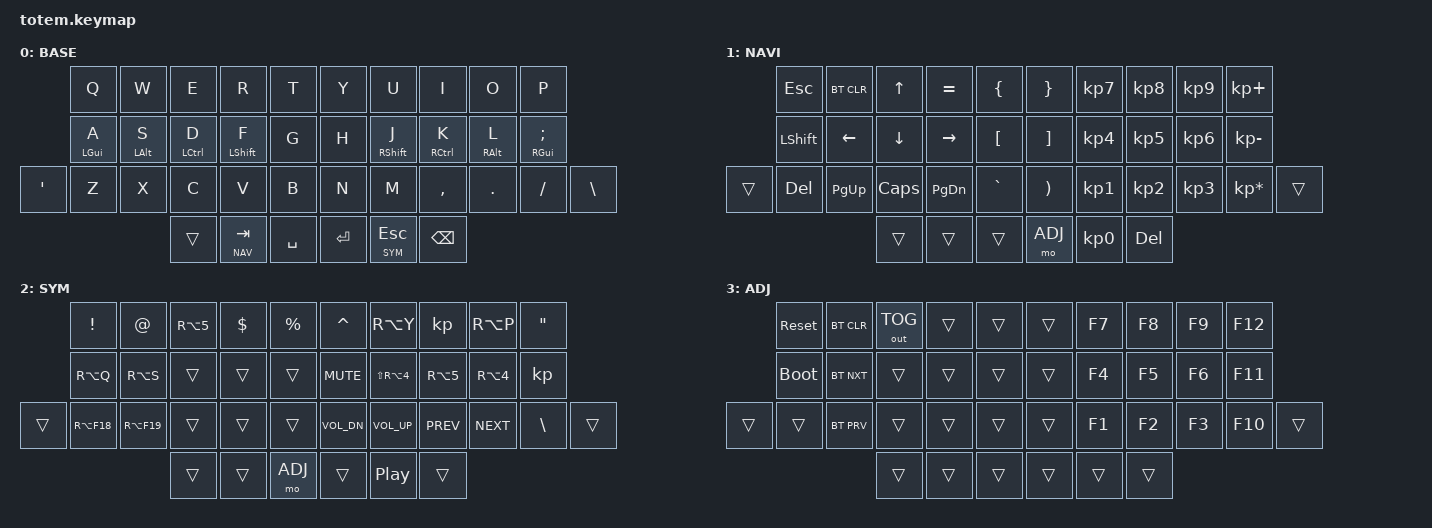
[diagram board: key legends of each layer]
//
//                                                        ▀▀▀▀▀     ▀▀▀▀▀          ▀▀█▀▀
//                                                        ▄▀▀▀▄  ▄  ▄▀▀▀▄  ▄  ▄▀▀▀▄  █  ▄▀▀▀▄
//                                                        █   █  █  █   █  █  █   █  █  █   █
//                                                         ▀▀▀   █   ▀▀▀   █   ▀▀▀   ▀   ▀▀▀
//                                                               █      ▄▄▄█▄▄▄    █   █  
//                                                               ▀      █  █  █     █▄█
//                                                             ▀▀▀▀▀    █  █  █      ▀
//                                                                      ▀  ▀  ▀
//
// ▄▄▄▄▄▄▄▄▄▄▄▄▄▄▄▄▄▄▄▄▄▄▄▄▄▄▄▄▄▄▄▄▄▄▄▄▄▄▄▄▄▄▄▄▄▄▄▄▄▄▄▄▄▄▄▄▄▄▄▄▄▄▄▄▄▄▄▄▄▄▄▄▄▄▄▄▄▄▄▄▄▄▄▄▄▄▄▄▄▄▄▄▄▄▄▄▄▄▄▄▄▄▄▄▄▄▄▄▄▄▄▄▄▄▄▄▄▄▄▄▄▄▄▄▄▄▄▄▄▄▄▄▄▄▄▄▄▄▄▄▄▄▄▄▄▄▄▄▄

#include <behaviors.dtsi>
#include <dt-bindings/zmk/bt.h>
#include <dt-bindings/zmk/keys.h>
#include <dt-bindings/zmk/outputs.h>

#define BASE 0
#define NAV  1
#define SYM  2
#define ADJ  3

&mt {
    quick-tap-ms = <100>;
    global-quick-tap;
    flavor = "tap-preferred";
    tapping-term-ms = <170>;
};

/ {
    combos {
        compatible = "zmk,combos";

        combo_esc {
            timeout-ms = <50>;
            key-positions = <0 1>;
            bindings = <&kp ESC>;
        };
    };

    macros {
    };

    keymap {
        compatible = "zmk,keymap";

        // ▄▄▄▄▄▄▄▄▄▄▄▄▄▄▄▄▄▄▄▄▄▄▄▄▄▄▄▄▄▄▄▄▄▄▄▄▄▄▄▄▄▄▄▄▄▄▄▄▄▄▄▄▄▄▄▄▄▄▄▄▄▄▄▄▄▄▄▄▄▄▄▄▄▄▄▄▄▄▄▄▄▄▄▄▄▄▄▄▄▄▄▄▄▄▄▄▄▄▄▄▄▄▄▄▄▄▄▄▄▄▄▄▄▄▄▄▄▄▄▄▄▄▄▄▄▄▄▄▄▄▄▄▄▄▄▄▄▄▄▄▄▄▄▄▄▄▄▄▄

                 base_layer {
// ┏━━━━━━━━━━━━━━━━━━━━━━━━━━━━━━━━━━━━━━━┓
label= "BASE"                              ;
// ┗━━━━━━━━━━━━━━━━━━━━━━━━━━━━━━━━━━━━━━━┛
//             ┏━━━━━━━━━━━┳━━━━━━━━━━━┳━━━━━━━━━━━┳━━━━━━━━━━━┳━━━━━━━━━━━┓   ┏━━━━━━━━━━━┳━━━━━━━━━━━┳━━━━━━━━━━━┳━━━━━━━━━━━┳━━━━━━━━━━━┓
//             ┃     Q     ┃     W     ┃     E     ┃     R     ┃     T     ┃   ┃     Y     ┃     U     ┃     I     ┃     O     ┃     P     ┃
//             ┣━━━━━━━━━━━╋━━━━━━━━━━━╋━━━━━━━━━━━╋━━━━━━━━━━━╋━━━━━━━━━━━┫   ┣━━━━━━━━━━━╋━━━━━━━━━━━╋━━━━━━━━━━━╋━━━━━━━━━━━╋━━━━━━━━━━━┫
//             ┃     A     ┃     s     ┃     D     ┃     F     ┃     G     ┃   ┃     H     ┃     J     ┃     K     ┃     L     ┃     ;     ┃
// ┏━━━━━━━━━━━╋━━━━━━━━━━━╋━━━━━━━━━━━╋━━━━━━━━━━━╋━━━━━━━━━━━╋━━━━━━━━━━━┫   ┣━━━━━━━━━━━╋━━━━━━━━━━━╋━━━━━━━━━━━╋━━━━━━━━━━━╋━━━━━━━━━━━╋━━━━━━━━━━━┓
// ┃     '     ┃     Z     ┃     X     ┃     C     ┃     V     ┃     B     ┃   ┃     N     ┃     M     ┃     ,     ┃     .     ┃     /     ┃     \     ┃
// ┗━━━━━━━━━━━┻━━━━━━━━━━━┻━━━━━━━━━━━╋━━━━━━━━━━━╋━━━━━━━━━━━╋━━━━━━━━━━━┫   ┣━━━━━━━━━━━╋━━━━━━━━━━━╋━━━━━━━━━━━╋━━━━━━━━━━━┻━━━━━━━━━━━┻━━━━━━━━━━━┛
//                                     ┃           ┃  NUM/TAB  ┃    SPC    ┃   ┃   ENTER   ┃  SYM/ESC  ┃   BSPC    ┃
//                                     ┗━━━━━━━━━━━┻━━━━━━━━━━━┻━━━━━━━━━━━┛   ┗━━━━━━━━━━━┻━━━━━━━━━━━┻━━━━━━━━━━━┛
 bindings = <
// ╷           ╷           ╷           ╷           ╷           ╷           ╷   ╷           ╷           ╷           ╷           ╷           ╷           ╷

                &kp Q       &kp W       &kp E       &kp R       &kp T           &kp Y       &kp U       &kp I       &kp O       &kp P
                &mt LGUI A  &mt LALT S  &mt LCTRL D &mt LSHFT F &kp G           &kp H       &mt RSHFT J &mt RCTRL K &mt RALT L  &mt RGUI SEMI
    &kp SQT     &kp Z       &kp X       &kp C       &kp V       &kp B           &kp N       &kp M       &kp COMMA   &kp DOT     &kp FSLH    &kp BSLH
                                        &trans      &lt NAV TAB &kp SPACE       &kp RET     &lt SYM ESC &kp BSPC
                        >;
                };

// ▄▄▄▄▄▄▄▄▄▄▄▄▄▄▄▄▄▄▄▄▄▄▄▄▄▄▄▄▄▄▄▄▄▄▄▄▄▄▄▄▄▄▄▄▄▄▄▄▄▄▄▄▄▄▄▄▄▄▄▄▄▄▄▄▄▄▄▄▄▄▄▄▄▄▄▄▄▄▄▄▄▄▄▄▄▄▄▄▄▄▄▄▄▄▄▄▄▄▄▄▄▄▄▄▄▄▄▄▄▄▄▄▄▄▄▄▄▄▄▄▄▄▄▄▄▄▄▄▄▄▄▄▄▄▄▄▄▄▄▄▄▄▄▄▄▄▄▄▄


                nav_layer {
// ┏━━━━━━━━━━━━━━━━━━━━━━━━━━━━━━━━━━━━━━━┓
label= "NAVI"                              ;
// ┗━━━━━━━━━━━━━━━━━━━━━━━━━━━━━━━━━━━━━━━┛
//             ┏━━━━━━━━━━━┳━━━━━━━━━━━┳━━━━━━━━━━━┳━━━━━━━━━━━┳━━━━━━━━━━━┓   ┏━━━━━━━━━━━┳━━━━━━━━━━━┳━━━━━━━━━━━┳━━━━━━━━━━━┳━━━━━━━━━━━┓
//             ┃           ┃           ┃     UP    ┃           ┃     -     ┃   ┃     {     ┃     }     ┃     7     ┃     8     ┃     9     ┃
//             ┣━━━━━━━━━━━╋━━━━━━━━━━━╋━━━━━━━━━━━╋━━━━━━━━━━━╋━━━━━━━━━━━┫   ┣━━━━━━━━━━━╋━━━━━━━━━━━╋━━━━━━━━━━━╋━━━━━━━━━━━╋━━━━━━━━━━━┫
//             ┃   SHIFT   ┃   LEFT    ┃    DOWN   ┃   RIGHT   ┃     =     ┃   ┃     [     ┃     ]     ┃     4     ┃     5     ┃     6     ┃
// ┏━━━━━━━━━━━╋━━━━━━━━━━━╋━━━━━━━━━━━╋━━━━━━━━━━━╋━━━━━━━━━━━╋━━━━━━━━━━━┫   ┣━━━━━━━━━━━╋━━━━━━━━━━━╋━━━━━━━━━━━╋━━━━━━━━━━━╋━━━━━━━━━━━╋━━━━━━━━━━━┓
// ┃           ┃           ┃   P UP    ┃  C LOCK   ┃  P DOWN   ┃     `     ┃   ┃     (     ┃     )     ┃     1     ┃     2     ┃     3     ┃           ┃
// ┗━━━━━━━━━━━┻━━━━━━━━━━━┻━━━━━━━━━━━╋━━━━━━━━━━━╋━━━━━━━━━━━╋━━━━━━━━━━━┫   ┣━━━━━━━━━━━╋━━━━━━━━━━━╋━━━━━━━━━━━╋━━━━━━━━━━━┻━━━━━━━━━━━┻━━━━━━━━━━━┛
//                                     ┃           ┃    TAB    ┃    SPC    ┃   ┃    ADJ    ┃           ┃     0     ┃
//                                     ┗━━━━━━━━━━━┻━━━━━━━━━━━┻━━━━━━━━━━━┛   ┗━━━━━━━━━━━┻━━━━━━━━━━━┻━━━━━━━━━━━┛
 bindings = <
// ╷           ╷           ╷           ╷           ╷           ╷           ╷   ╷           ╷           ╷           ╷           ╷           ╷           ╷

                &kp ESC     &bt BT_CLR  &kp UP      &kp EQUAL   &kp LBRC        &kp RBRC    &kp KP_N7   &kp KP_N8   &kp KP_N9   &kp KP_PLUS
                &kp LSHFT   &kp LEFT    &kp DOWN    &kp RIGHT   &kp LBKT        &kp RBKT    &kp KP_N4   &kp KP_N5   &kp KP_N6   &kp KP_MINUS
    &trans      &kp DEL     &kp PG_UP   &kp CAPS    &kp PG_DN   &kp GRAVE       &kp RPAR    &kp KP_N1   &kp KP_N2   &kp KP_N3   &kp KP_MULTIPLY &trans      
                                        &trans      &trans      &trans          &mo ADJ     &kp KP_N0   &kp DEL      
                        >;
                };

// ▄▄▄▄▄▄▄▄▄▄▄▄▄▄▄▄▄▄▄▄▄▄▄▄▄▄▄▄▄▄▄▄▄▄▄▄▄▄▄▄▄▄▄▄▄▄▄▄▄▄▄▄▄▄▄▄▄▄▄▄▄▄▄▄▄▄▄▄▄▄▄▄▄▄▄▄▄▄▄▄▄▄▄▄▄▄▄▄▄▄▄▄▄▄▄▄▄▄▄▄▄▄▄▄▄▄▄▄▄▄▄▄▄▄▄▄▄▄▄▄▄▄▄▄▄▄▄▄▄▄▄▄▄▄▄▄▄▄▄▄▄▄▄▄▄▄▄▄▄


                sim_layer {
// ┏━━━━━━━━━━━━━━━━━━━━━━━━━━━━━━━━━━━━━━━┓
label= "SYM"                               ;
// ┗━━━━━━━━━━━━━━━━━━━━━━━━━━━━━━━━━━━━━━━┛
//             ┏━━━━━━━━━━━┳━━━━━━━━━━━┳━━━━━━━━━━━┳━━━━━━━━━━━┳━━━━━━━━━━━┓   ┏━━━━━━━━━━━┳━━━━━━━━━━━┳━━━━━━━━━━━┳━━━━━━━━━━━┳━━━━━━━━━━━┓
//             ┃     !     ┃     @     ┃     €     ┃     $     ┃     %     ┃   ┃     ˆ     ┃     Ü     ┃           ┃     Ö     ┃     "     ┃
//             ┣━━━━━━━━━━━╋━━━━━━━━━━━╋━━━━━━━━━━━╋━━━━━━━━━━━╋━━━━━━━━━━━┫   ┣━━━━━━━━━━━╋━━━━━━━━━━━╋━━━━━━━━━━━╋━━━━━━━━━━━╋━━━━━━━━━━━┫
//             ┃     Ä     ┃     SZ    ┃           ┃           ┃           ┃   ┃   MUTE    ┃   YEN     ┃   EURO    ┃  POUND    ┃           ┃
// ┏━━━━━━━━━━━╋━━━━━━━━━━━╋━━━━━━━━━━━╋━━━━━━━━━━━╋━━━━━━━━━━━╋━━━━━━━━━━━┫   ┣━━━━━━━━━━━╋━━━━━━━━━━━╋━━━━━━━━━━━╋━━━━━━━━━━━╋━━━━━━━━━━━╋━━━━━━━━━━━┓
// ┃           ┃  EMAIL1   ┃  EMAIL2   ┃           ┃           ┃           ┃   ┃   VOL-    ┃   VOL+    ┃   LAST    ┃   NEXT    ┃     \     ┃           ┃
// ┗━━━━━━━━━━━┻━━━━━━━━━━━┻━━━━━━━━━━━╋━━━━━━━━━━━╋━━━━━━━━━━━╋━━━━━━━━━━━┫   ┣━━━━━━━━━━━╋━━━━━━━━━━━╋━━━━━━━━━━━╋━━━━━━━━━━━┻━━━━━━━━━━━┻━━━━━━━━━━━┛
//                                     ┃           ┃           ┃    ADJ    ┃   ┃           ┃           ┃           ┃
//                                     ┗━━━━━━━━━━━┻━━━━━━━━━━━┻━━━━━━━━━━━┛   ┗━━━━━━━━━━━┻━━━━━━━━━━━┻━━━━━━━━━━━┛
 bindings = <
// ╷           ╷           ╷           ╷           ╷           ╷           ╷   ╷           ╷           ╷           ╷           ╷           ╷           ╷

                &kp EXCL    &kp AT      &kp RA(5)    &kp DLLR    &kp PRCNT       &kp CARET   &kp RA(Y)    &kp          &kp RA(P)  &kp DQT       
                &kp RA(Q)   &kp RA(S)   &trans       &trans      &trans          &kp C_MUTE  &kp LS(RA(N4)) &kp RA(N5) &kp RA(N4) &kp   
    &trans      &kp RA(F18) &kp RA(F19) &trans      &trans       &trans          &kp C_VOL_DN &kp C_VOL_UP &kp C_PREV &kp C_NEXT  &kp BSLH   &trans         
                                        &trans      &trans        &mo ADJ         &trans      &kp C_PP    &trans      
                        >;
                };

// ▄▄▄▄▄▄▄▄▄▄▄▄▄▄▄▄▄▄▄▄▄▄▄▄▄▄▄▄▄▄▄▄▄▄▄▄▄▄▄▄▄▄▄▄▄▄▄▄▄▄▄▄▄▄▄▄▄▄▄▄▄▄▄▄▄▄▄▄▄▄▄▄▄▄▄▄▄▄▄▄▄▄▄▄▄▄▄▄▄▄▄▄▄▄▄▄▄▄▄▄▄▄▄▄▄▄▄▄▄▄▄▄▄▄▄▄▄▄▄▄▄▄▄▄▄▄▄▄▄▄▄▄▄▄▄▄▄▄▄▄▄▄▄▄▄▄▄▄▄


                adjust_layer {
// ┏━━━━━━━━━━━━━━━━━━━━━━━━━━━━━━━━━━━━━━━┓
label= "ADJ"                               ;
// ┗━━━━━━━━━━━━━━━━━━━━━━━━━━━━━━━━━━━━━━━┛
//             ┏━━━━━━━━━━━┳━━━━━━━━━━━┳━━━━━━━━━━━┳━━━━━━━━━━━┳━━━━━━━━━━━┓   ┏━━━━━━━━━━━┳━━━━━━━━━━━┳━━━━━━━━━━━┳━━━━━━━━━━━┳━━━━━━━━━━━┓
//             ┃   RESET   ┃ BT CLEAR  ┃  OUT TOG  ┃           ┃           ┃   ┃           ┃    F7     ┃    F8     ┃    F9     ┃    F12    ┃
//             ┣━━━━━━━━━━━╋━━━━━━━━━━━╋━━━━━━━━━━━╋━━━━━━━━━━━╋━━━━━━━━━━━┫   ┣━━━━━━━━━━━╋━━━━━━━━━━━╋━━━━━━━━━━━╋━━━━━━━━━━━╋━━━━━━━━━━━┫
//             ┃ BOOTLOAD  ┃ BT NEXT   ┃           ┃           ┃           ┃   ┃           ┃    F4     ┃    F5     ┃    F6     ┃    F11    ┃
// ┏━━━━━━━━━━━╋━━━━━━━━━━━╋━━━━━━━━━━━╋━━━━━━━━━━━╋━━━━━━━━━━━╋━━━━━━━━━━━┫   ┣━━━━━━━━━━━╋━━━━━━━━━━━╋━━━━━━━━━━━╋━━━━━━━━━━━╋━━━━━━━━━━━╋━━━━━━━━━━━┓
// ┃           ┃           ┃ BT PREV   ┃           ┃           ┃           ┃   ┃           ┃    F1     ┃    F2     ┃    F3     ┃    F10    ┃           ┃
// ┗━━━━━━━━━━━┻━━━━━━━━━━━┻━━━━━━━━━━━╋━━━━━━━━━━━╋━━━━━━━━━━━╋━━━━━━━━━━━┫   ┣━━━━━━━━━━━╋━━━━━━━━━━━╋━━━━━━━━━━━╋━━━━━━━━━━━┻━━━━━━━━━━━┻━━━━━━━━━━━┛
//                                     ┃           ┃           ┃           ┃   ┃           ┃           ┃           ┃
//                                     ┗━━━━━━━━━━━┻━━━━━━━━━━━┻━━━━━━━━━━━┛   ┗━━━━━━━━━━━┻━━━━━━━━━━━┻━━━━━━━━━━━┛
 bindings = <
// ╷           ╷           ╷           ╷           ╷           ╷           ╷   ╷           ╷           ╷           ╷           ╷           ╷           ╷

                &sys_reset  &bt BT_CLR &out OUT_TOG &trans      &trans          &trans      &kp F7      &kp F8      &kp F9      &kp F12
                &bootloader &bt BT_NXT  &trans      &trans      &trans          &trans      &kp F4      &kp F5      &kp F6      &kp F11  
    &trans      &trans      &bt BT_PRV  &trans      &trans      &trans          &trans      &kp F1      &kp F2      &kp F3      &kp F10     &trans         
                                        &trans      &trans      &trans          &trans      &trans      &trans      
                        >;
                };
    };
};
